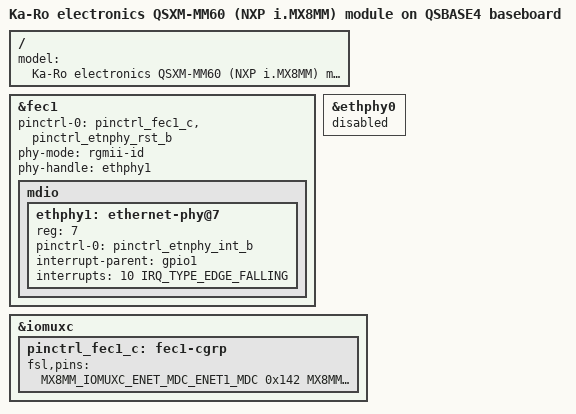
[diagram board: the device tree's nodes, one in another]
// SPDX-License-Identifier: (GPL-2.0 OR MIT)
/*
 * Copyright (C) 2022 Lothar Waßmann <LW@KARO-electronics.de>
 *
 */

/dts-v1/;

#include "imx8mm-qsxm-mm60-qsbase3.dts"

/ {
	model = "Ka-Ro electronics QSXM-MM60 (NXP i.MX8MM) module on QSBASE4 baseboard";
};

&fec1 {
	pinctrl-0 = <&pinctrl_fec1_c &pinctrl_etnphy_rst_b>;
	phy-mode = "rgmii-id";
	phy-handle = <&ethphy1>;

	mdio {
		#address-cells = <1>;
		#size-cells = <0>;

		ethphy1: ethernet-phy@7 {
			reg = <7>;
			pinctrl-names = "default";
			pinctrl-0 = <&pinctrl_etnphy_int_b>;
			interrupt-parent = <&gpio1>;
			interrupts = <10 IRQ_TYPE_EDGE_FALLING>;
		};
	};
};

&ethphy0 {
	status = "disabled";
};

&iomuxc {
	pinctrl_fec1_c: fec1-cgrp {
		fsl,pins = <
			    MX8MM_IOMUXC_ENET_MDC_ENET1_MDC		0x142
			    MX8MM_IOMUXC_ENET_MDIO_ENET1_MDIO		0x142
			    MX8MM_IOMUXC_ENET_TXC_ENET1_RGMII_TXC	0x40000016
			    MX8MM_IOMUXC_ENET_TD0_ENET1_RGMII_TD0	0x016
			    MX8MM_IOMUXC_ENET_TD1_ENET1_RGMII_TD1	0x016
			    MX8MM_IOMUXC_ENET_TD2_ENET1_RGMII_TD2	0x016
			    MX8MM_IOMUXC_ENET_TD3_ENET1_RGMII_TD3	0x016
			    MX8MM_IOMUXC_ENET_TX_CTL_ENET1_RGMII_TX_CTL	0x016
			    MX8MM_IOMUXC_ENET_RD0_ENET1_RGMII_RD0	0x110 /* MODE0 */
			    MX8MM_IOMUXC_ENET_RD1_ENET1_RGMII_RD1	0x150 /* MODE1 */
			    MX8MM_IOMUXC_ENET_RD2_ENET1_RGMII_RD2	0x150 /* MODE2 */
			    MX8MM_IOMUXC_ENET_RD3_ENET1_RGMII_RD3	0x150 /* MODE3 */
			    MX8MM_IOMUXC_ENET_RXC_ENET1_RGMII_RXC	0x156 /* PHYAD2 */
			    MX8MM_IOMUXC_ENET_RX_CTL_ENET1_RGMII_RX_CTL	0x156 /* CLK125_EN */
			    MX8MM_IOMUXC_GPIO1_IO00_GPIO1_IO0		0x110 /* LED_MODE */
		>;
	};
};
